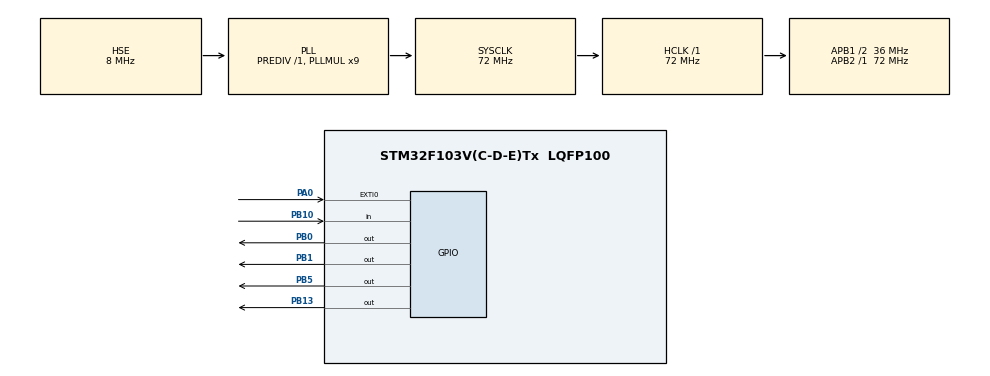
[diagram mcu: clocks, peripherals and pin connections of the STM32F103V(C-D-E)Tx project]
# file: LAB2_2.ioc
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Mcu.Family=STM32F1
Mcu.Name=STM32F103V(C-D-E)Tx
Mcu.Package=LQFP100
NVIC.EXTI0_IRQn=true\:0\:0\:false\:false\:true\:true\:true
NVIC.PriorityGroup=NVIC_PRIORITYGROUP_4
OSC_IN.Mode=HSE-External-Oscillator
OSC_IN.Signal=RCC_OSC_IN
OSC_OUT.Mode=HSE-External-Oscillator
OSC_OUT.Signal=RCC_OSC_OUT
PA0-WKUP.GPIO_ModeDefaultEXTI=GPIO_MODE_IT_RISING
PA0-WKUP.Signal=GPXTI0
PA13.Mode=Serial_Wire
PA13.Signal=SYS_JTMS-SWDIO
PA14.Mode=Serial_Wire
PA14.Signal=SYS_JTCK-SWCLK
PB0.GPIO_Speed=GPIO_SPEED_FREQ_HIGH
PB0.PinState=GPIO_PIN_SET
PB0.Signal=GPIO_Output
PB1.GPIO_Speed=GPIO_SPEED_FREQ_HIGH
PB1.PinState=GPIO_PIN_SET
PB1.Signal=GPIO_Output
PB10.GPIO_PuPd=GPIO_PULLDOWN
PB10.Signal=GPIO_Input
PB13.Signal=GPIO_Output
PB5.GPIO_Speed=GPIO_SPEED_FREQ_HIGH
PB5.PinState=GPIO_PIN_SET
PB5.Signal=GPIO_Output
PC14-OSC32_IN.Mode=LSE-External-Oscillator
PC14-OSC32_IN.Signal=RCC_OSC32_IN
PC15-OSC32_OUT.Mode=LSE-External-Oscillator
PC15-OSC32_OUT.Signal=RCC_OSC32_OUT
ProjectManager.HeapSize=0x200
ProjectManager.StackSize=0x400
ProjectManager.TargetToolchain=MDK-ARM V5
RCC.AHBFreq_Value=72000000
RCC.APB1CLKDivider=RCC_HCLK_DIV2
RCC.APB1Freq_Value=36000000
RCC.APB1TimFreq_Value=72000000
RCC.APB2Freq_Value=72000000
RCC.APB2TimFreq_Value=72000000
RCC.HCLKFreq_Value=72000000
RCC.PLLMUL=RCC_PLL_MUL9
RCC.PLLSourceVirtual=RCC_PLLSOURCE_HSE
RCC.SYSCLKFreq_VALUE=72000000
RCC.SYSCLKSource=RCC_SYSCLKSOURCE_PLLCLK
RCC.USBFreq_Value=72000000
board=custom

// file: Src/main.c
/* USER CODE BEGIN Header */
/**
  ******************************************************************************
  * @file           : main.c
  * @brief          : Main program body
  ******************************************************************************
  * @attention
  *
  * <h2><center>&copy; Copyright (c) 2021 STMicroelectronics.
  * All rights reserved.</center></h2>
  *
  * This software component is licensed by ST under BSD 3-Clause license,
  * the "License"; You may not use this file except in compliance with the
  * License. You may obtain a copy of the License at:
  *                        opensource.org/licenses/BSD-3-Clause
  *
  ******************************************************************************
  */
/* USER CODE END Header */

#include "main.h"

void SystemClock_Config(void);
static void MX_GPIO_Init(void);

int main(void)
{

  /* MCU Configuration--------------------------------------------------------*/

  /* Reset of all peripherals, Initializes the Flash interface and the Systick. */
  HAL_Init();

  /* USER CODE BEGIN Init */
	GPIO_PinState current_state = GPIO_PIN_RESET;
	int i = -1;
  /* USER CODE END Init */

  /* Configure the system clock */
  SystemClock_Config();

  /* Initialize all configured peripherals */
  MX_GPIO_Init();

  /* Infinite loop */
  while (1)
  {
		if ((current_state == GPIO_PIN_RESET) && (HAL_GPIO_ReadPin(GPIOB, GPIO_PIN_10) == GPIO_PIN_SET)){
			i += 1;
			current_state = GPIO_PIN_SET;
		}
		if ((current_state == GPIO_PIN_SET) && (HAL_GPIO_ReadPin(GPIOB, GPIO_PIN_10) == GPIO_PIN_RESET)){
			current_state = GPIO_PIN_RESET;
		}
		if (i>=0){
			switch(i%3){
				case(0):
					HAL_GPIO_WritePin(GPIOB, GPIO_PIN_5, GPIO_PIN_RESET); // R
					HAL_GPIO_WritePin(GPIOB, GPIO_PIN_0, GPIO_PIN_SET); // G
					HAL_GPIO_WritePin(GPIOB, GPIO_PIN_1, GPIO_PIN_SET); // B
					break;
				case(1):
					HAL_GPIO_WritePin(GPIOB, GPIO_PIN_5, GPIO_PIN_SET); // R
					HAL_GPIO_WritePin(GPIOB, GPIO_PIN_0, GPIO_PIN_RESET); // G
					HAL_GPIO_WritePin(GPIOB, GPIO_PIN_1, GPIO_PIN_SET); // B
					break;
				default:
					HAL_GPIO_WritePin(GPIOB, GPIO_PIN_5, GPIO_PIN_SET); // R
					HAL_GPIO_WritePin(GPIOB, GPIO_PIN_0, GPIO_PIN_SET); // G
					HAL_GPIO_WritePin(GPIOB, GPIO_PIN_1, GPIO_PIN_RESET); // B
			}
		}
  }
}

void SystemClock_Config(void)
{
  RCC_OscInitTypeDef RCC_OscInitStruct = {0};
  RCC_ClkInitTypeDef RCC_ClkInitStruct = {0};

  /** Initializes the CPU, AHB and APB busses clocks
  */
  RCC_OscInitStruct.OscillatorType = RCC_OSCILLATORTYPE_HSE;
  RCC_OscInitStruct.HSEState = RCC_HSE_ON;
  RCC_OscInitStruct.HSEPredivValue = RCC_HSE_PREDIV_DIV1;
  RCC_OscInitStruct.HSIState = RCC_HSI_ON;
  RCC_OscInitStruct.PLL.PLLState = RCC_PLL_ON;
  RCC_OscInitStruct.PLL.PLLSource = RCC_PLLSOURCE_HSE;
  RCC_OscInitStruct.PLL.PLLMUL = RCC_PLL_MUL9;
  if (HAL_RCC_OscConfig(&RCC_OscInitStruct) != HAL_OK)
  {
    Error_Handler();
  }
  /** Initializes the CPU, AHB and APB busses clocks
  */
  RCC_ClkInitStruct.ClockType = RCC_CLOCKTYPE_HCLK|RCC_CLOCKTYPE_SYSCLK
                              |RCC_CLOCKTYPE_PCLK1|RCC_CLOCKTYPE_PCLK2;
  RCC_ClkInitStruct.SYSCLKSource = RCC_SYSCLKSOURCE_PLLCLK;
  RCC_ClkInitStruct.AHBCLKDivider = RCC_SYSCLK_DIV1;
  RCC_ClkInitStruct.APB1CLKDivider = RCC_HCLK_DIV2;
  RCC_ClkInitStruct.APB2CLKDivider = RCC_HCLK_DIV1;

  if (HAL_RCC_ClockConfig(&RCC_ClkInitStruct, FLASH_LATENCY_2) != HAL_OK)
  {
    Error_Handler();
  }
}

static void MX_GPIO_Init(void)
{
  GPIO_InitTypeDef GPIO_InitStruct = {0};

  /* GPIO Ports Clock Enable */
  __HAL_RCC_GPIOC_CLK_ENABLE();
  __HAL_RCC_GPIOA_CLK_ENABLE();
  __HAL_RCC_GPIOB_CLK_ENABLE();

  /*Configure GPIO pin Output Level */
  HAL_GPIO_WritePin(GPIOB, GPIO_PIN_0|GPIO_PIN_1|GPIO_PIN_5, GPIO_PIN_SET);

  /*Configure GPIO pin Output Level */
  HAL_GPIO_WritePin(GPIOB, GPIO_PIN_13, GPIO_PIN_RESET);

  /*Configure GPIO pin : PA0 */
  GPIO_InitStruct.Pin = GPIO_PIN_0;
  GPIO_InitStruct.Mode = GPIO_MODE_IT_RISING;
  GPIO_InitStruct.Pull = GPIO_NOPULL;
  HAL_GPIO_Init(GPIOA, &GPIO_InitStruct);

  /*Configure GPIO pins : PB0 PB1 PB5 */
  GPIO_InitStruct.Pin = GPIO_PIN_0|GPIO_PIN_1|GPIO_PIN_5;
  GPIO_InitStruct.Mode = GPIO_MODE_OUTPUT_PP;
  GPIO_InitStruct.Pull = GPIO_NOPULL;
  GPIO_InitStruct.Speed = GPIO_SPEED_FREQ_HIGH;
  HAL_GPIO_Init(GPIOB, &GPIO_InitStruct);

  /*Configure GPIO pin : PB10 */
  GPIO_InitStruct.Pin = GPIO_PIN_10;
  GPIO_InitStruct.Mode = GPIO_MODE_INPUT;
  GPIO_InitStruct.Pull = GPIO_PULLDOWN;
  HAL_GPIO_Init(GPIOB, &GPIO_InitStruct);

  /*Configure GPIO pin : PB13 */
  GPIO_InitStruct.Pin = GPIO_PIN_13;
  GPIO_InitStruct.Mode = GPIO_MODE_OUTPUT_PP;
  GPIO_InitStruct.Pull = GPIO_NOPULL;
  GPIO_InitStruct.Speed = GPIO_SPEED_FREQ_LOW;
  HAL_GPIO_Init(GPIOB, &GPIO_InitStruct);

  /* EXTI interrupt init*/
  HAL_NVIC_SetPriority(EXTI0_IRQn, 0, 0);
  HAL_NVIC_EnableIRQ(EXTI0_IRQn);

}

void Error_Handler(void)
{
}

/************************ (C) COPYRIGHT STMicroelectronics *****END OF FILE****/
